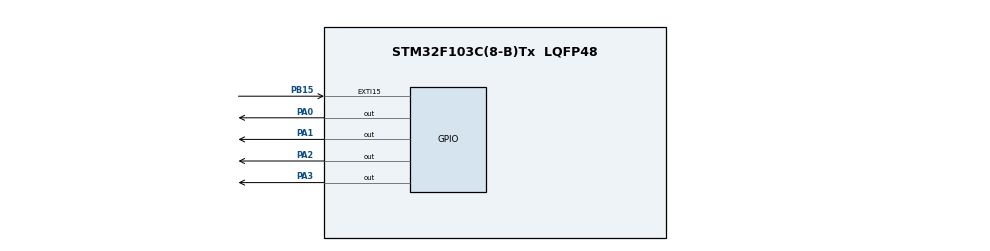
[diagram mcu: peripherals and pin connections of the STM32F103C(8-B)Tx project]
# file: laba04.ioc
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Mcu.Family=STM32F1
Mcu.Name=STM32F103C(8-B)Tx
Mcu.Package=LQFP48
NVIC.EXTI15_10_IRQn=true\:0\:0\:false\:true\:true\:2\:true\:true\:true
NVIC.PriorityGroup=NVIC_PRIORITYGROUP_4
NVIC.TIM2_IRQn=true\:0\:0\:false\:true\:true\:1\:true\:true\:true
PA0-WKUP.Signal=GPIO_Output
PA1.Signal=GPIO_Output
PA2.Signal=GPIO_Output
PA3.Signal=GPIO_Output
PB15.Signal=GPXTI15
ProjectManager.HeapSize=0x200
ProjectManager.StackSize=0x400
ProjectManager.TargetToolchain=STM32CubeIDE
RCC.APB1Freq_Value=8000000
RCC.APB2Freq_Value=8000000
TIM2.Period=200
TIM2.Prescaler=800
TIM2.TIM_MasterOutputTrigger=TIM_TRGO_UPDATE
VP_SYS_VS_ND.Mode=No_Debug
VP_TIM2_VS_ClockSourceINT.Mode=Internal
board=custom

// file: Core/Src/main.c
/* USER CODE BEGIN Header */
/**
  ******************************************************************************
  * @file           : main.c
  * @brief          : Main program body
  ******************************************************************************
  */
/* USER CODE END Header */

#include "main.h"
#include <stdbool.h>
#include "tim.h"

/* USER CODE BEGIN PV */
volatile bool blinkEnable = true;      // Чи вмикати миготіння таймером
volatile bool buttonPressed = false;   // Стан кнопки
/* USER CODE END PV */

void SystemClock_Config(void);
static void MX_GPIO_Init(void);

static void MX_NVIC_Init(void);

int main(void)
{
  HAL_Init();
  SystemClock_Config();

  MX_GPIO_Init();
  MX_TIM2_Init();
  MX_NVIC_Init();

  HAL_TIM_Base_Start_IT(&htim2); // Запуск таймера з перериванням

  while (1)
  {
    HAL_GPIO_TogglePin(GPIOA, GPIO_PIN_4); // Блимання PA4 незалежно
    HAL_Delay(500);
  }
}

void SystemClock_Config(void)
{
  RCC_OscInitTypeDef RCC_OscInitStruct = {0};
  RCC_ClkInitTypeDef RCC_ClkInitStruct = {0};

  RCC_OscInitStruct.OscillatorType = RCC_OSCILLATORTYPE_HSI;
  RCC_OscInitStruct.HSIState = RCC_HSI_ON;
  RCC_OscInitStruct.HSICalibrationValue = RCC_HSICALIBRATION_DEFAULT;
  RCC_OscInitStruct.PLL.PLLState = RCC_PLL_NONE;
  HAL_RCC_OscConfig(&RCC_OscInitStruct);

  RCC_ClkInitStruct.ClockType = RCC_CLOCKTYPE_HCLK|RCC_CLOCKTYPE_SYSCLK
                              |RCC_CLOCKTYPE_PCLK1|RCC_CLOCKTYPE_PCLK2;
  RCC_ClkInitStruct.SYSCLKSource = RCC_SYSCLKSOURCE_HSI;
  RCC_ClkInitStruct.AHBCLKDivider = RCC_SYSCLK_DIV1;
  RCC_ClkInitStruct.APB1CLKDivider = RCC_HCLK_DIV1;
  RCC_ClkInitStruct.APB2CLKDivider = RCC_HCLK_DIV1;

  HAL_RCC_ClockConfig(&RCC_ClkInitStruct, FLASH_LATENCY_0);
}

static void MX_NVIC_Init(void)
{
  HAL_NVIC_SetPriority(EXTI15_10_IRQn, 0, 0);
  HAL_NVIC_EnableIRQ(EXTI15_10_IRQn);
  HAL_NVIC_SetPriority(TIM2_IRQn, 1, 0);
  HAL_NVIC_EnableIRQ(TIM2_IRQn);
}

static void MX_GPIO_Init(void)
{
  GPIO_InitTypeDef GPIO_InitStruct = {0};

  __HAL_RCC_GPIOA_CLK_ENABLE();
  __HAL_RCC_GPIOB_CLK_ENABLE();

  // Світлодіоди PA0–PA3
  GPIO_InitStruct.Pin = GPIO_PIN_0|GPIO_PIN_1|GPIO_PIN_2|GPIO_PIN_3;
  GPIO_InitStruct.Mode = GPIO_MODE_OUTPUT_PP;
  GPIO_InitStruct.Pull = GPIO_NOPULL;
  GPIO_InitStruct.Speed = GPIO_SPEED_FREQ_LOW;
  HAL_GPIO_Init(GPIOA, &GPIO_InitStruct);

  // Додатковий світлодіод PA4
  GPIO_InitStruct.Pin = GPIO_PIN_4;
  HAL_GPIO_Init(GPIOA, &GPIO_InitStruct);
  HAL_GPIO_WritePin(GPIOA, GPIO_PIN_4, GPIO_PIN_RESET);

  // Кнопка PB15 з перериванням
  GPIO_InitStruct.Pin = GPIO_PIN_15;
  GPIO_InitStruct.Mode = GPIO_MODE_IT_RISING_FALLING;
  GPIO_InitStruct.Pull = GPIO_NOPULL;
  HAL_GPIO_Init(GPIOB, &GPIO_InitStruct);
}

/* USER CODE BEGIN 4 */
void HAL_TIM_PeriodElapsedCallback(TIM_HandleTypeDef *htim)
{
  if (htim->Instance == TIM2 && blinkEnable)
  {
    HAL_GPIO_TogglePin(GPIOA, GPIO_PIN_0);
    HAL_GPIO_TogglePin(GPIOA, GPIO_PIN_1);
    HAL_GPIO_TogglePin(GPIOA, GPIO_PIN_2);
    HAL_GPIO_TogglePin(GPIOA, GPIO_PIN_3);
  }
}

void HAL_GPIO_EXTI_Callback(uint16_t GPIO_Pin)
{
  if (GPIO_Pin == GPIO_PIN_15)
  {
    buttonPressed = !buttonPressed;
    blinkEnable = !buttonPressed; // Якщо натиснуто — зупинити блимання
  }
}
/* USER CODE END 4 */
void Error_Handler(void)
{
  __disable_irq();
  while (1) {}
}
